AUTOSAR XML (schema 00049)
package /SwComponent/AdaptiveApplication
  adaptive application sw component type CM
  adaptive application sw component type Camera
    provide port PPortCamera: provided-interface=SvCamera
  adaptive application sw component type EM
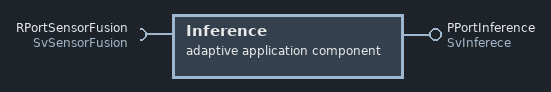
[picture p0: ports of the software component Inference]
  adaptive application sw component type Inference
    provide port PPortInference: provided-interface=SvInferece
    require port RPortSensorFusion: required-interface=SvSensorFusion
  adaptive application sw component type Lidar
    provide port PPortLidar: provided-interface=SvLidar
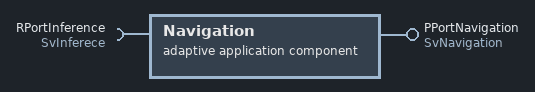
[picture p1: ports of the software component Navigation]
  adaptive application sw component type Navigation
    provide port PPortNavigation: provided-interface=SvNavigation
    require port RPortInference: required-interface=SvInferece
  adaptive application sw component type SM
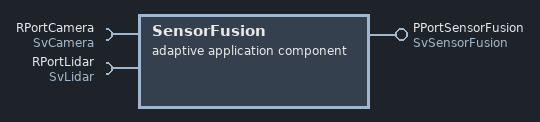
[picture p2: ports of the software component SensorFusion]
  adaptive application sw component type SensorFusion
    provide port PPortSensorFusion: provided-interface=SvSensorFusion
    require port RPortCamera: required-interface=SvCamera
    require port RPortLidar: required-interface=SvLidar
  adaptive application sw component type Servo
    require port RPortNavigation: required-interface=SvNavigation
package /AdaptiveApplication/DltConfig
  8 x dlt log channel to process mapping:
    DltLogChannelToProcessMapping_CM_TO_CM: dlt-log-channel=CM, process=CM
    DltLogChannelToProcessMapping_Camera_TO_Camera: dlt-log-channel=Camera, process=Camera
    DltLogChannelToProcessMapping_EM_TO_EM: dlt-log-channel=EM, process=EM
    DltLogChannelToProcessMapping_Inference_TO_Inference: dlt-log-channel=Inference, process=Inference
    DltLogChannelToProcessMapping_Lidar_TO_Lidar: dlt-log-channel=Lidar, process=Lidar
    DltLogChannelToProcessMapping_Navigation_TO_Navigation: dlt-log-channel=Navigation, process=Navigation
    DltLogChannelToProcessMapping_SensorFusion_TO_SensorFusion: dlt-log-channel=SensorFusion, process=SensorFusion
    DltLogChannelToProcessMapping_Servo_TO_Servo: dlt-log-channel=Servo, process=Servo
package /AdaptiveApplication/Executable
  8 x executable, all with logging-behavior=USES-LOGGING, reporting-behavior=REPORTS-EXECUTION-STATE, version=1.0.0:
    CM: category=PLATFORM_LEVEL
      root sw component prototype PARA: application-type=CM
    Camera: category=APPLICATION_LEVEL
      root sw component prototype AA: application-type=Camera
    EM: category=PLATFORM_LEVEL
    Inference: category=APPLICATION_LEVEL
      root sw component prototype AA: application-type=Inference
    Lidar: category=APPLICATION_LEVEL
      root sw component prototype AA: application-type=Lidar
    Navigation: category=APPLICATION_LEVEL
      root sw component prototype AA: application-type=Navigation
    SensorFusion: category=APPLICATION_LEVEL
      root sw component prototype AA: application-type=SensorFusion
    Servo: category=APPLICATION_LEVEL
      root sw component prototype AA: application-type=Servo
package /AdaptiveApplication/Manifest
  10 x service instance to port prototype mapping:
    Camera_AA_PPortCamera: port-prototype=AA.PPortCamera, service-instance=Provider_SvCamera_AACamera
    Inference_AA_PPortInference: port-prototype=AA.PPortInference, service-instance=Provider_SvInferece_AAInference
    Inference_AA_RPortSensorFusion: port-prototype=AA.RPortSensorFusion, service-instance=Consumer_SvSensorFusion_AAInference
    Lidar_AA_PPortLidar: port-prototype=AA.PPortLidar, service-instance=Provider_SvLidar_AALidar
    Navigation_AA_PPortNavigation: port-prototype=AA.PPortNavigation, service-instance=Provider_SvNavigation_AANavigation
    Navigation_AA_RPortInference: port-prototype=AA.RPortInference, service-instance=Consumer_SvInferece_AANavigation
    SensorFusion_AA_PPortSensorFusion: port-prototype=AA.PPortSensorFusion, service-instance=Provider_SvSensorFusion_AASensorFusion
    SensorFusion_AA_RPortCamera: port-prototype=AA.RPortCamera, service-instance=Consumer_SvCamera_AASensorFusion
    SensorFusion_AA_RPortLidar: port-prototype=AA.RPortLidar, service-instance=Consumer_SvLidar_AASensorFusion
    Servo_AA_RPortNavigation: port-prototype=AA.RPortNavigation, service-instance=Consumer_SvNavigation_AAServo
package /AdaptiveApplication/Process
  8 x process:
    CM: executable=CM, state-dependent-startup-config{function-group-state=[MachineFG.Startup, MachineFG.Restart, MachineFG.Shutdown, MachineFG.Verify], resource-group=ResourceGroup, startup-config=CM}
      process state machine CM: type=ProcessState
    Camera: executable=Camera, state-dependent-startup-config{execution-dependency=CM.Running, function-group-state=MachineFG.Startup, resource-group=ResourceGroup, startup-config=Camera}
      process state machine Camera: type=ProcessState
    EM: executable=EM
      process state machine EM: type=ProcessState
    Inference: executable=Inference, state-dependent-startup-config{execution-dependency=CM.Running, function-group-state=MachineFG.Startup, resource-group=ResourceGroup, startup-config=Inference}
      process state machine Inference: type=ProcessState
    Lidar: executable=Lidar, state-dependent-startup-config{execution-dependency=CM.Running, function-group-state=MachineFG.Startup, resource-group=ResourceGroup, startup-config=Lidar}
      process state machine Lidar: type=ProcessState
    Navigation: executable=Navigation, state-dependent-startup-config{execution-dependency=CM.Running, function-group-state=MachineFG.Startup, resource-group=ResourceGroup, startup-config=Navigation}
      process state machine Navigation: type=ProcessState
    SensorFusion: executable=SensorFusion, state-dependent-startup-config{execution-dependency=CM.Running, function-group-state=MachineFG.Startup, resource-group=ResourceGroup, startup-config=SensorFusion}
      process state machine SensorFusion: type=ProcessState
    Servo: executable=Servo, state-dependent-startup-config{execution-dependency=CM.Running, function-group-state=MachineFG.Startup, resource-group=ResourceGroup, startup-config=Servo}
      process state machine Servo: type=ProcessState
package /AdaptiveApplication/StartupConfig
  startup config set StartupConfigSet
    7 x startup config, all with scheduling-policy=SCHED_OTHER, scheduling-priority=0:
      CM: timeout={enter-timeout-value=1.0, exit-timeout-value=1.0}
      Camera: timeout={enter-timeout-value=5.0, exit-timeout-value=1.0}
      Inference: timeout={enter-timeout-value=1.0, exit-timeout-value=1.0}
      Lidar: timeout={enter-timeout-value=5.0, exit-timeout-value=1.0}
      Navigation: timeout={enter-timeout-value=1.0, exit-timeout-value=1.0}
      SensorFusion: timeout={enter-timeout-value=1.0, exit-timeout-value=1.0}
      Servo: timeout={enter-timeout-value=1.0, exit-timeout-value=1.0}
package /DataType/Implementation/CPP
  11 x std cpp implementation data type, all with category=VALUE:
    bool: type-emitter=FundamentalType
    double: type-emitter=FundamentalType
    float: type-emitter=FundamentalType
    int16_t: header-file=cstdint
    int32_t: header-file=cstdint
    int64_t: header-file=cstdint
    int8_t: header-file=cstdint
    uint16_t: header-file=cstdint
    uint32_t: header-file=cstdint
    uint64_t: header-file=cstdint
    uint8_t: header-file=cstdint
package /PortInterface/Service
  5 x service interface:
    SvCamera
      namespaces:
        symbol props deepracer
        symbol props service
        symbol props camera
      events:
        data CamEvent: type=uint8_t
    SvInferece
      namespaces:
        symbol props deepracer
        symbol props service
        symbol props inference
      events:
        data InfEvent: type=uint8_t
    SvLidar
      namespaces:
        symbol props deepracer
        symbol props service
        symbol props lidar
      events:
        data LidEvent: type=uint8_t
    SvNavigation
      namespaces:
        symbol props deepracer
        symbol props service
        symbol props navigation
      events:
        data NavEvent: type=uint8_t
    SvSensorFusion
      namespaces:
        symbol props deepracer
        symbol props service
        symbol props sensorfusion
      events:
        data SFEvent: type=uint8_t
package /Platform
  machine DeepracerMachine: machine-design=Ecu, trusted-platform-executable-launch-behavior=NO-TRUSTED-PLATFORM-SUPPORT
    module-instantiations:
      os module instantiation Linux
        resource group ResourceGroup
      log and trace instantiation LogAndTraceInstantiation: dlt-ecu-id=Ecu
        8 x dlt log channel, all with log-trace-log-modes=CONSOLE:
          CM: application-id=CM, context-id=CM, log-trace-default-log-level=ERROR
          Camera: application-id=CAM, context-id=CAM, log-trace-default-log-level=INFO
          EM: application-id=EM, context-id=EM, log-trace-default-log-level=ERROR
          Inference: application-id=INFE, context-id=INFE, log-trace-default-log-level=INFO
          Lidar: application-id=LID, context-id=LID, log-trace-default-log-level=INFO
          Navigation: application-id=NAVI, context-id=NAVI, log-trace-default-log-level=INFO
          SensorFusion: application-id=SEFU, context-id=SEFU, log-trace-default-log-level=INFO
          Servo: application-id=SERV, context-id=SERV, log-trace-default-log-level=INFO
    processor CPU  # Intel Atom
      processor core Core: core-id=0
package /Platform/FunctionGroup
  function group set FunctionGroupSet
    function-groups:
      mode declaration group prototype MachineFG: type=MachineState
package /Platform/ProcessToMachine
  process to machine mapping set ProcessToMachineMappingSet
    8 x process to machine mapping, all with machine=DeepracerMachine:
      ProcessToMachineMapping_CM_TO_DeepracerMachine_TO_UnknownModule: process=CM
      ProcessToMachineMapping_Camera_TO_DeepracerMachine_TO_UnknownModule: process=Camera
      ProcessToMachineMapping_EM_TO_DeepracerMachine_TO_UnknownModule: process=EM
      ProcessToMachineMapping_ProcessInference_TO_MachineManifest_Machine_TO_UnknownModule: process=Inference
      ProcessToMachineMapping_ProcessLidar_TO_MachineManifest_Machine_TO_UnknownModule: process=Lidar
      ProcessToMachineMapping_ProcessNavigation_TO_MachineManifest_Machine_TO_UnknownModule: process=Navigation
      ProcessToMachineMapping_ProcessSensorFusion_TO_MachineManifest_Machine_TO_UnknownModule: process=SensorFusion
      ProcessToMachineMapping_ProcessServo_TO_MachineManifest_Machine_TO_UnknownModule: process=Servo
package /System
  system System: category=MACHINE_DESIGN_EXTRACT, system-version=1.0.0  # AWS DeepRacer Evo(Camera: 1, Lidar: 1)
package /System/Service/Deployment
  5 x someip service interface deployment, all with service-interface-version={major-version=1, minor-version=0}:
    SvCamera: service-interface=SvCamera, service-interface-id=80
      someip event deployment CamEvent: event=CamEvent, event-id=1, transport-protocol=UDP
      someip event group Eventgroup_CamEvent: event-group-id=1, event=CamEvent
    SvInferece: service-interface=SvInferece, service-interface-id=83
      someip event deployment InfEvent: event=InfEvent, event-id=1, transport-protocol=UDP
      someip event group Eventgroup_InfEvent: event-group-id=1, event=InfEvent
    SvLidar: service-interface=SvLidar, service-interface-id=81
      someip event deployment LidEvent: event=LidEvent, event-id=1, transport-protocol=UDP
      someip event group Eventgroup_LidEvent: event-group-id=1, event=LidEvent
    SvNavigation: service-interface=SvNavigation, service-interface-id=84
      someip event deployment NavEvent: event=NavEvent, event-id=1, transport-protocol=UDP
      someip event group Eventgroup_NavEvent: event-group-id=1, event=NavEvent
    SvSensorFusion: service-interface=SvSensorFusion, service-interface-id=82
      someip event deployment SFEvent: event=SFEvent, event-id=1, transport-protocol=UDP
      someip event group Eventgroup_SFEvent: event-group-id=1, event=SFEvent
package /System/Service/Endpoint
  10 x someip service instance to machine mapping, all with communication-connector=eth0:
    Mapping_Consumer_SvCamera_AASensorFusion: service-instance=Consumer_SvCamera_AASensorFusion, tcp-port=21000, udp-port=21000
    Mapping_Consumer_SvInferece_AANavigation: service-instance=Consumer_SvInferece_AANavigation, tcp-port=21003, udp-port=21003
    Mapping_Consumer_SvLidar_AASensorFusion: service-instance=Consumer_SvLidar_AASensorFusion, tcp-port=21001, udp-port=21001
    Mapping_Consumer_SvNavigation_AAServo: service-instance=Consumer_SvNavigation_AAServo, tcp-port=21004, udp-port=21004
    Mapping_Consumer_SvSensorFusion_AAInference: service-instance=Consumer_SvSensorFusion_AAInference, tcp-port=21002, udp-port=21002
    Mapping_Provider_SvCamera_AACamera: service-instance=Provider_SvCamera_AACamera, tcp-port=20000, udp-port=20000
    Mapping_Provider_SvInferece_AAInference: service-instance=Provider_SvInferece_AAInference, tcp-port=20003, udp-port=20003
    Mapping_Provider_SvLidar_AALidar: service-instance=Provider_SvLidar_AALidar, tcp-port=20001, udp-port=20001
    Mapping_Provider_SvNavigation_AANavigation: service-instance=Provider_SvNavigation_AANavigation, tcp-port=20004, udp-port=20004
    Mapping_Provider_SvSensorFusion_AASensorFusion: service-instance=Provider_SvSensorFusion_AASensorFusion, tcp-port=20002, udp-port=20002
package /System/Service/Instance
  5 x required someip service instance, all with required-minor-version=ANY, required-service-instance-id=1, sd-client-config=SdClientConfig, version-driven-find-behavior=EXACT-OR-ANY-MINOR-VERSION:
    Consumer_SvCamera_AASensorFusion: service-interface-deployment=SvCamera
      someip required event group Eventgroup_CamEvent: event-group=Eventgroup_CamEvent, sd-client-event-group-timing-config=SubscriptionTimingConfig
    Consumer_SvInferece_AANavigation: service-interface-deployment=SvInferece
      someip required event group Eventgroup_InfEvent: event-group=Eventgroup_InfEvent, sd-client-event-group-timing-config=SubscriptionTimingConfig
    Consumer_SvLidar_AASensorFusion: service-interface-deployment=SvLidar
      someip required event group Eventgroup_LidEvent: event-group=Eventgroup_LidEvent, sd-client-event-group-timing-config=SubscriptionTimingConfig
    Consumer_SvNavigation_AAServo: service-interface-deployment=SvNavigation
      someip required event group Eventgroup_NavEvent: event-group=Eventgroup_NavEvent, sd-client-event-group-timing-config=SubscriptionTimingConfig
    Consumer_SvSensorFusion_AAInference: service-interface-deployment=SvSensorFusion
      someip required event group Eventgroup_SFEvent: event-group=Eventgroup_SFEvent, sd-client-event-group-timing-config=SubscriptionTimingConfig
  5 x provided someip service instance, all with sd-server-config=SdServerConfig, service-instance-id=1:
    Provider_SvCamera_AACamera: service-interface-deployment=SvCamera, someip-event-props=CamEvent
      someip provided event group Eventgroup_CamEvent: event-group=Eventgroup_CamEvent, multicast-threshold=0
    Provider_SvInferece_AAInference: service-interface-deployment=SvInferece, someip-event-props=InfEvent
      someip provided event group Eventgroup_InfEvent: event-group=Eventgroup_InfEvent, multicast-threshold=0
    Provider_SvLidar_AALidar: service-interface-deployment=SvLidar, someip-event-props=LidEvent
      someip provided event group Eventgroup_LidEvent: event-group=Eventgroup_LidEvent, multicast-threshold=0
    Provider_SvNavigation_AANavigation: service-interface-deployment=SvNavigation, someip-event-props=NavEvent
      someip provided event group Eventgroup_NavEvent: event-group=Eventgroup_NavEvent, multicast-threshold=0
    Provider_SvSensorFusion_AASensorFusion: service-interface-deployment=SvSensorFusion, someip-event-props=SFEvent
      someip provided event group Eventgroup_SFEvent: event-group=Eventgroup_SFEvent, multicast-threshold=0
package /System/Service/TimingConfig
  someip sd client service instance config SdClientConfig: initial-find-behavior={initial-delay-max-value=0.2, initial-delay-min-value=0.1, initial-repetitions-base-delay=0.1, initial-repetitions-max=4}, service-find-time-to-live=16777215
  someip sd server service instance config SdServerConfig: initial-offer-behavior={initial-delay-max-value=0.2, initial-delay-min-value=0.1, initial-repetitions-base-delay=0.1, initial-repetitions-max=3}, offer-cyclic-delay=0.5, request-response-delay={max-value=0.0, min-value=0.0}, service-offer-time-to-live=16777215
  someip sd client event group timing config SubscriptionTimingConfig: request-response-delay={max-value=0.0, min-value=0.0}, time-to-live=16777215
package /System/VehicleTopology/Cluster
  ethernet cluster EthernetCluster  # DeepRacer IP address
    ethernet physical channel PhysicalChannel: category=WIRED, comm-connectors=eth0
      network endpoint EcuEndpoint: network-endpoint-addresses=ipv-4-configuration={ipv-4-address=127.0.0.1, ipv-4-address-source=FIXED}
      network endpoint SdEndpoint: network-endpoint-addresses=ipv-4-configuration={ipv-4-address=224.0.0.1, ipv-4-address-source=FIXED}
package /System/VehicleTopology/Ecu
  machine design Ecu: service-discover-configs=someip-service-discovery={multicast-sd-ip-address=SdEndpoint, someip-service-discovery-port=30490}  # DeepRacer Network Node
    user defined communication connector IPC
    ethernet communication connector eth0: unicast-network-endpoint=EcuEndpoint
package /StateMachine
  mode declaration group MachineState: initial-mode=Off
    5 x mode:
      Off
      Restart
      Shutdown
      Startup
      Verify
  mode declaration group ProcessState: initial-mode=Idle
    4 x mode:
      Idle
      Running
      Starting
      Terminated
